VERSION ""

NS_ :

BS_:

BU_: EON XXX INTERCEPTOR ANY ACTUATOR SAFETY

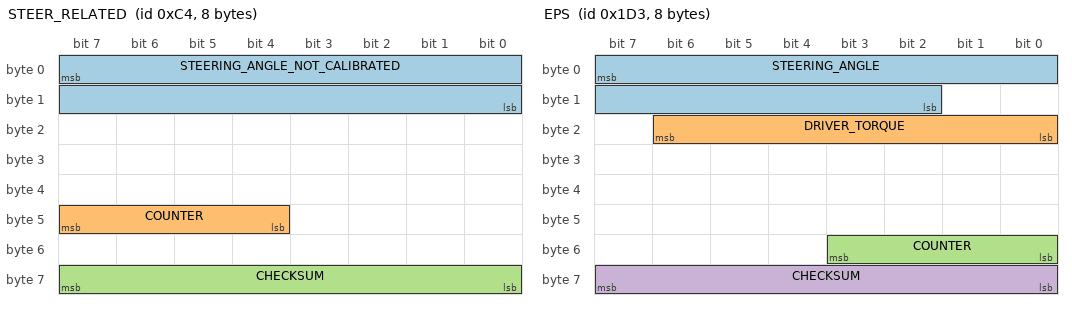
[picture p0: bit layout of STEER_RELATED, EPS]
BO_ 196 STEER_RELATED: 8 XXX
 SG_ STEERING_ANGLE_NOT_CALIBRATED : 7|16@0+ (1,0) [0|65535] "" XXX
 SG_ COUNTER : 47|4@0+ (1,0) [0|15] "" XXX
 SG_ CHECKSUM : 63|8@0+ (1,0) [0|255] "" XXX

BO_ 250 GAS: 8 XXX
 SG_ GAS_THROTTLE : 31|8@0+ (0.01,0) [0|255] "" XXX
 SG_ GAS_PEDAL_PRESSURE : 53|6@0+ (0.01,0) [0|63] "" XXX

BO_ 269 TRANSMISSION: 8 XXX
 SG_ GEAR : 43|4@0+ (1,0) [0|15] "" XXX

BO_ 467 EPS: 8 XXX
 SG_ STEERING_ANGLE : 7|14@0+ (0.1,-773) [0|16383] "" XXX
 SG_ DRIVER_TORQUE : 22|7@0+ (1,0) [0|127] "" XXX
 SG_ COUNTER : 51|4@0+ (1,0) [0|15] "" XXX
 SG_ CHECKSUM : 63|8@0+ (1,0) [0|255] "" XXX

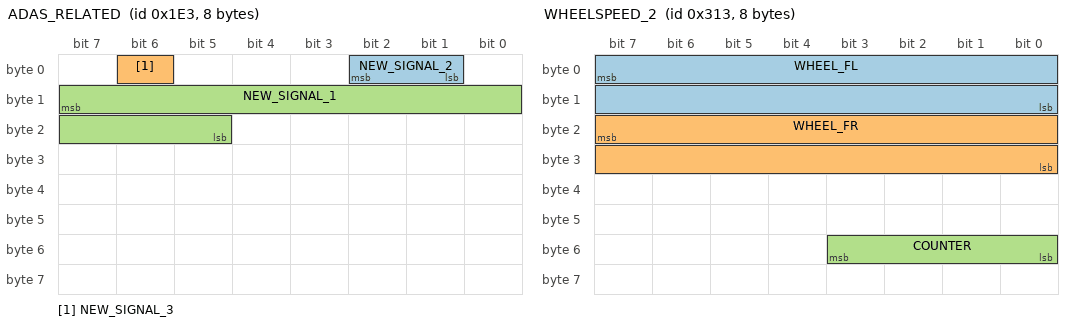
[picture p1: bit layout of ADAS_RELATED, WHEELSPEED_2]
BO_ 483 ADAS_RELATED: 8 XXX
 SG_ NEW_SIGNAL_2 : 1|2@1+ (1,0) [0|3] "" XXX
 SG_ NEW_SIGNAL_3 : 6|1@0+ (1,0) [0|1] "" XXX
 SG_ NEW_SIGNAL_1 : 15|11@0+ (1,-1024) [0|2047] "" XXX

BO_ 608 SPEED_RELATED: 8 XXX
 SG_ NON_CAL_SPEED1 : 1|9@0+ (1,0) [0|511] "" XXX
 SG_ NON_CAL_SPEED2 : 17|9@0+ (1,0) [0|511] "" XXX

BO_ 666 BRAKE_PEDAL: 8 XXX
 SG_ BRAKE_PRESSURE : 18|9@0+ (0.002,0) [0|511] "" XXX
 SG_ AUTO_HOLD : 40|1@0+ (1,0) [0|1] "" XXX

BO_ 787 WHEELSPEED_2: 8 XXX
 SG_ WHEEL_FL : 7|16@0+ (0.01,0) [0|65535] "" XXX
 SG_ WHEEL_FR : 23|16@0+ (0.01,0) [0|65535] "" XXX
 SG_ COUNTER : 51|4@0+ (1,0) [0|15] "" XXX

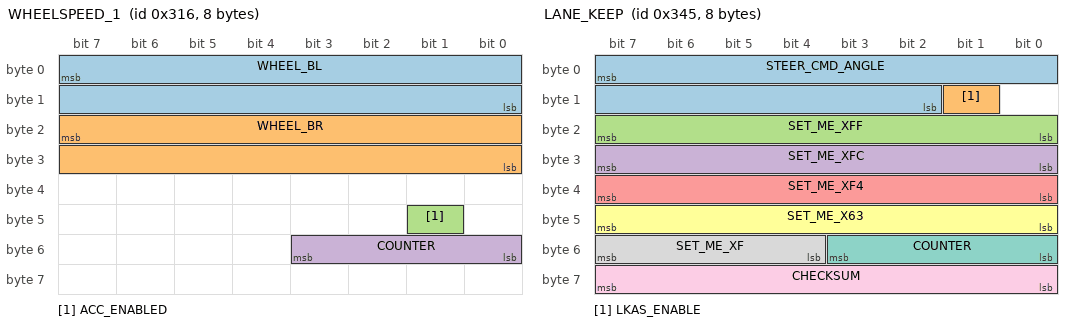
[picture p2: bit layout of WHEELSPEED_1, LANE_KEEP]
BO_ 790 WHEELSPEED_1: 8 XXX
 SG_ WHEEL_BL : 7|16@0+ (0.01,0) [0|65535] "" XXX
 SG_ WHEEL_BR : 23|16@0+ (0.01,0) [0|65535] "" XXX
 SG_ ACC_ENABLED : 41|1@0+ (1,0) [0|1] "" XXX
 SG_ COUNTER : 51|4@0+ (1,0) [0|15] "" XXX

BO_ 837 LANE_KEEP: 8 XXX
 SG_ STEER_CMD_ANGLE : 7|14@0+ (0.1,-773) [0|16383] "" XXX
 SG_ LKAS_ENABLE : 9|1@0+ (1,0) [0|1] "" XXX
 SG_ SET_ME_XFF : 23|8@0+ (1,0) [0|255] "" XXX
 SG_ SET_ME_XFC : 31|8@0+ (1,0) [0|255] "" XXX
 SG_ SET_ME_XF4 : 39|8@0+ (1,0) [0|255] "" XXX
 SG_ SET_ME_X63 : 47|8@0+ (1,0) [0|255] "" XXX
 SG_ COUNTER : 51|4@0+ (1,0) [0|15] "" XXX
 SG_ SET_ME_XF : 55|4@0+ (1,0) [0|15] "" XXX
 SG_ CHECKSUM : 63|8@0+ (1,0) [0|255] "" XXX

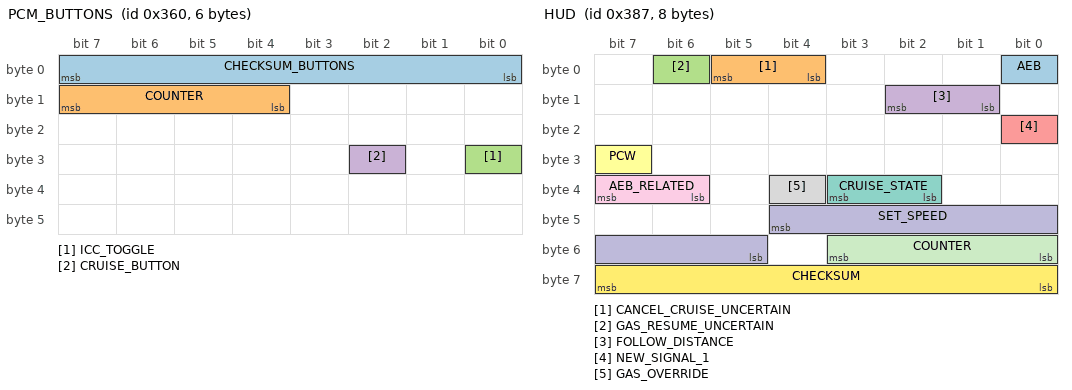
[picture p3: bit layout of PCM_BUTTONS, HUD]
BO_ 864 PCM_BUTTONS: 6 XXX
 SG_ CHECKSUM_BUTTONS : 7|8@0+ (1,0) [0|255] "" XXX
 SG_ COUNTER : 15|4@0+ (1,0) [0|15] "" XXX
 SG_ ICC_TOGGLE : 24|1@0+ (1,0) [0|1] "" XXX
 SG_ CRUISE_BUTTON : 26|1@0+ (1,0) [0|1] "" XXX

BO_ 903 HUD: 8 XXX
 SG_ AEB : 0|1@0+ (1,0) [0|1] "" XXX
 SG_ CANCEL_CRUISE_UNCERTAIN : 5|2@0+ (1,0) [0|3] "" XXX
 SG_ GAS_RESUME_UNCERTAIN : 6|1@0+ (1,0) [0|1] "" XXX
 SG_ FOLLOW_DISTANCE : 9|2@1+ (1,0) [0|3] "" XXX
 SG_ NEW_SIGNAL_1 : 16|1@0+ (1,0) [0|1] "" XXX
 SG_ PCW : 31|1@0+ (1,0) [0|1] "" XXX
 SG_ CRUISE_STATE : 34|2@1+ (1,0) [0|3] "" XXX
 SG_ GAS_OVERRIDE : 36|1@0+ (1,0) [0|1] "" XXX
 SG_ AEB_RELATED : 39|2@0+ (1,0) [0|3] "" XXX
 SG_ SET_SPEED : 44|8@0+ (1,0) [0|255] "" XXX
 SG_ COUNTER : 51|4@0+ (1,0) [0|15] "" XXX
 SG_ CHECKSUM : 63|8@0+ (1,0) [0|255] "" XXX

BO_ 913 STALK: 8 XXX
 SG_ RIGHT_BLINKER : 16|1@0+ (1,0) [0|1] "" XXX
 SG_ LEFT_BLINKER : 17|1@0+ (1,0) [0|1] "" XXX

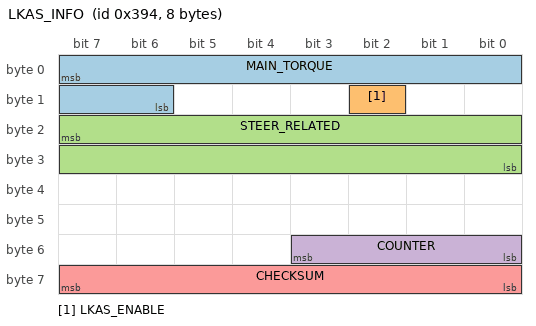
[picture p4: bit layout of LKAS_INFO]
BO_ 916 LKAS_INFO: 8 XXX
 SG_ MAIN_TORQUE : 7|10@0+ (1,0) [0|1023] "" XXX
 SG_ LKAS_ENABLE : 10|1@0+ (1,0) [0|1] "" XXX
 SG_ STEER_RELATED : 23|16@0+ (1,-32637) [0|65535] "" XXX
 SG_ COUNTER : 51|4@0+ (1,0) [0|15] "" XXX
 SG_ CHECKSUM : 63|8@0+ (1,0) [0|255] "" XXX

BO_ 990 ACC_UNCERTAIN: 8 XXX
 SG_ NEW_SIGNAL_2 : 8|9@0+ (1,-260) [0|511] "" XXX

CM_ SG_ 269 GEAR "D is 4, N is 3, R is 2, P is 1";
CM_ SG_ 666 AUTO_HOLD "Only gear D it will be active";
CM_ SG_ 903 FOLLOW_DISTANCE "1 is 3 BAR, 2 is 2 BAR, 3 is 1 BAR";
CM_ SG_ 903 CRUISE_STATE "3 is ENABLE, 2 is READY, 1 is IDLE";
